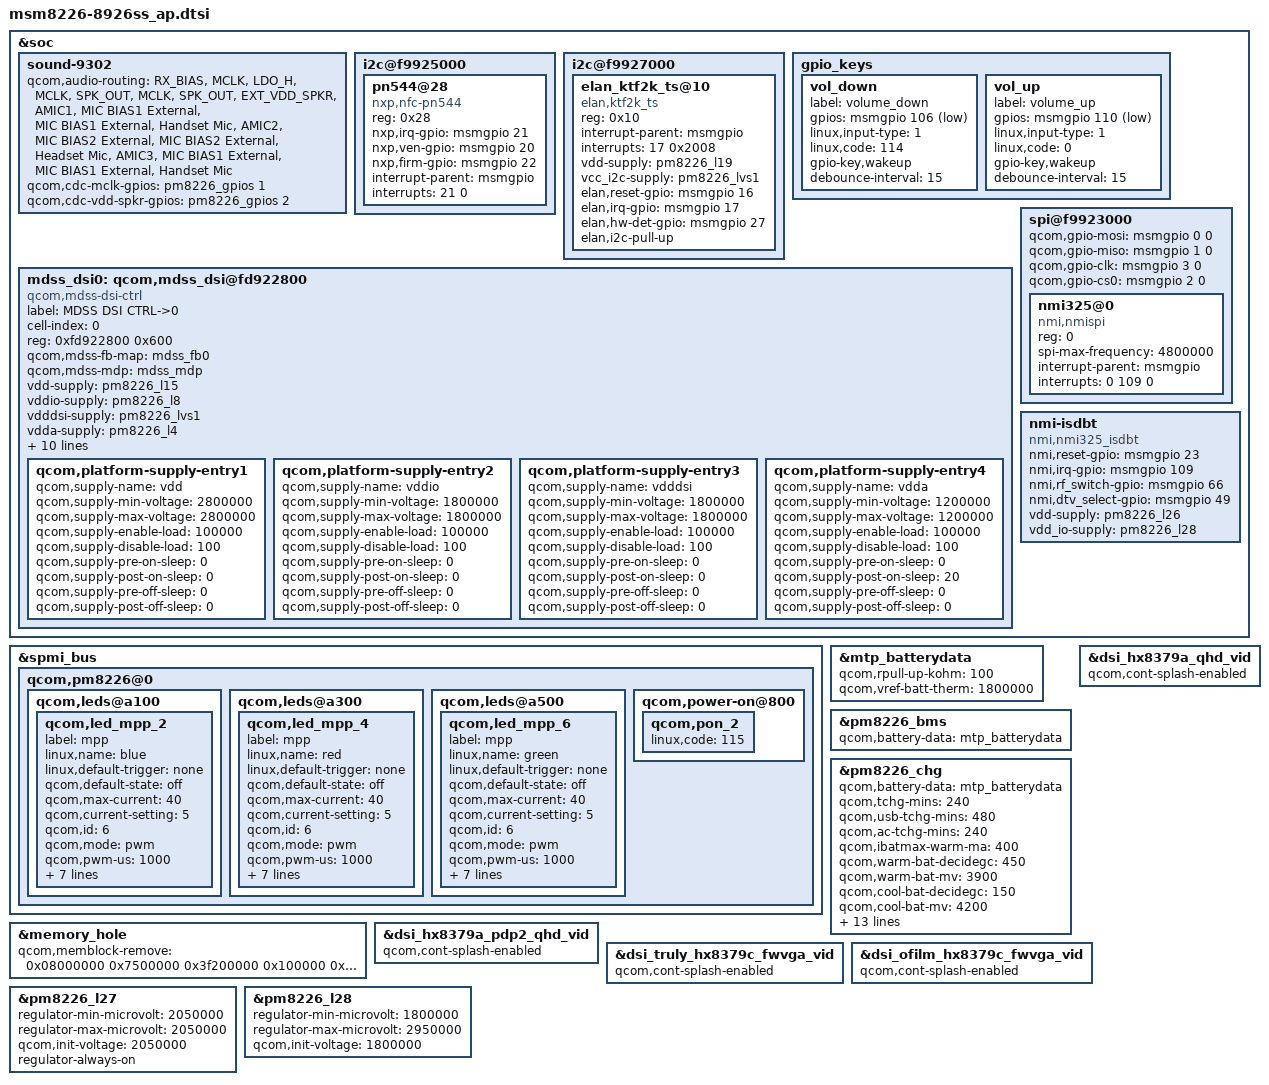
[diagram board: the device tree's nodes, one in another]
/include/ "msm8226-arima.dtsi"

/*[Arima5908][32703][StevenChen] LCM driver porting 2014/01/03 begin */
/include/ "dsi-panel-truly-hx8379a-qhd-video.dtsi"
/*[Arima5908][32703][StevenChen] LCM driver porting 2014/01/03 end */

/* --- [All][Main][Audio][DMS][LuboLu] Porting audio. 20140103 begin --- */
&soc {
	sound-9302 {
		qcom,audio-routing =
			"RX_BIAS", "MCLK",
			"LDO_H", "MCLK",
			"SPK_OUT", "MCLK",
			"SPK_OUT", "EXT_VDD_SPKR",
			"AMIC1", "MIC BIAS1 External",
			"MIC BIAS1 External", "Handset Mic",
			"AMIC2", "MIC BIAS2 External",
			"MIC BIAS2 External", "Headset Mic",
			"AMIC3", "MIC BIAS1 External",
			"MIC BIAS1 External", "Handset Mic";

		qcom,cdc-mclk-gpios = <&pm8226_gpios 1 0>;
		qcom,cdc-vdd-spkr-gpios = <&pm8226_gpios 2 0>;
	};
};
/* --- [All][Main][Audio][DMS][LuboLu] 20140103 end   --- */

/* --- [All][Main][NFC][DMS][LuboLu] Porting NFC(NXP PN547). 20140103 begin --- */
&soc {
		i2c@f9925000 { /* BLSP1 QUP3 */
		pn544@28 {
			compatible = "nxp,nfc-pn544";
			reg = <0x28>;
			nxp,irq-gpio = <&msmgpio 21 0x00>;
			nxp,ven-gpio = <&msmgpio 20 0x00>;
			nxp,firm-gpio = <&msmgpio 22 0x00>;
			interrupt-parent = <&msmgpio>;
			interrupts = <21 0>;
		};
	};
/* #//[All][Main][TP][32772]20140106,Eric, Porting elan-ektf3135 touch driver. */
               i2c@f9927000 { /* BLSP1 QUP5 */
		elan_ktf2k_ts@10{
			compatible = "elan,ktf2k_ts";
			reg = <0x10>;
			interrupt-parent = <&msmgpio>;
			interrupts = <17 0x2008>;
			vdd-supply = <&pm8226_l19>;
			vcc_i2c-supply = <&pm8226_lvs1>;
			elan,reset-gpio = <&msmgpio 16 0x00>;
			elan,irq-gpio = <&msmgpio 17 0x2008>;
			elan,hw-det-gpio = <&msmgpio 27 0x00>;			
			elan,i2c-pull-up;
		};
         };
/*   #//[All][Main][TP][32772]end */

/* [Arima5908][32780][JessicaTseng] [All][Main][Key][DMS]Porting volume_down key for PDP1 20140106 start */
	gpio_keys {
		vol_down {
			label = "volume_down";
			gpios = <&msmgpio 110 0x1>;
			linux,input-type = <1>;
			linux,code = <114>;
			gpio-key,wakeup;
			debounce-interval = <15>;
		};
	};
/* [Arima5908][32780][JessicaTseng] [All][Main][Key][DMS]Porting volume_down key for PDP1 20140106 end */
};
/* --- [All][Main][NFC][DMS][LuboLu] 20140103 end   --- */

/* [Arima5908][32708][JessicaTseng] [All][Main][LED][DMS]Porting R/G/B LED 20140103 start */
&spmi_bus {
	qcom,pm8226@0 {
		qcom,leds@a100 {
			status = "okay";
			qcom,led_mpp_2 {
				label = "mpp";
				linux,name = "blue";
				linux,default-trigger = "none";
				qcom,default-state = "off";
				qcom,max-current = <40>;
				qcom,current-setting = <5>;
				qcom,id = <6>;
				qcom,mode = "pwm";
				qcom,pwm-us = <1000>;
				qcom,source-sel = <14>;
				qcom,mode-ctrl = <0x60>;
				qcom,pwm-channel = <3>;
/* [Arima5908][33453][JessicaTseng] [All][Main][LED][DMS]Enable LED blinking function 20140127 start */
				qcom,start-idx = <40>;
/* [Arima5908][33453][JessicaTseng] [All][Main][LED][DMS]Enable LED blinking function 20140127 end */
				qcom,ramp-step-ms = <120>;
				qcom,duty-pcts = [00 00 50 99 99 99 50 00];
				qcom,use-blink;
			};
		};

		qcom,leds@a300 {
			status = "okay";
			qcom,led_mpp_4 {
				label = "mpp";
				linux,name = "green";
				linux,default-trigger = "none";
				qcom,default-state = "off";
				qcom,max-current = <40>;
				qcom,current-setting = <5>;
				qcom,id = <6>;
				qcom,mode = "pwm";
				qcom,pwm-us = <1000>;
				qcom,source-sel = <8>;
				qcom,mode-ctrl = <0x60>;
				qcom,pwm-channel = <0>;
/* [Arima5908][33453][JessicaTseng] [All][Main][LED][DMS]Enable LED blinking function 20140127 start */
				qcom,start-idx = <20>;
/* [Arima5908][33453][JessicaTseng] [All][Main][LED][DMS]Enable LED blinking function 20140127 end */
				qcom,ramp-step-ms = <120>;
				qcom,duty-pcts = [00 00 50 99 99 99 50 00];
				qcom,use-blink;
			};
		};

		qcom,leds@a500 {
			status = "okay";
			qcom,led_mpp_6 {
				label = "mpp";
				linux,name = "red";
				linux,default-trigger = "none";
				qcom,default-state = "off";
				qcom,max-current = <40>;
				qcom,current-setting = <5>;
				qcom,id = <6>;
				qcom,mode = "pwm";
				qcom,pwm-us = <1000>;
				qcom,mode-ctrl = <0x60>;
				qcom,source-sel = <10>;
				qcom,pwm-channel = <5>;
				qcom,start-idx = <1>;
				qcom,ramp-step-ms = <120>;
				qcom,duty-pcts = [00 00 50 99 99 99 50 00];
				qcom,use-blink;
			};
		};

/* [Arima5908][32719][JessicaTseng] [All][Main][KEY][DMS]Porting reset key 20140103 start */
		qcom,power-on@800 {
			qcom,pon_2 {
				linux,code = <0>;
			};
		};
/* [Arima5908][32719][JessicaTseng] [All][Main][KEY][DMS]Porting reset key 20140103 end */
	};
};
/* [Arima5908][32708][JessicaTseng] [All][Main][LED][DMS]Porting R/G/B LED 20140103 end */

/*[Arima5908][32742][bozhi_lin] modify battery capacity to 2300mA for BA950 20140108 begin*/
&mtp_batterydata{
	qcom,rpull-up-kohm = <100>;
	qcom,vref-batt-therm = <1800000>;
	/include/ "batterydata-8926ss_dp.dtsi"
};

&pm8226_bms {
	qcom,battery-data = <&mtp_batterydata>;
};

&pm8226_chg {
	qcom,battery-data = <&mtp_batterydata>;
};
/*[Arima5908][32742][bozhi_lin] 20140108 end  */

/*[Arima5908][32703][StevenChen] LCM driver porting 2014/01/03 begin */			
&mdss_dsi0 {
	qcom,dsi-pref-prim-pan = <&dsi_hx8379a_qhd_vid>;
};

&dsi_hx8379a_qhd_vid { 
	qcom,cont-splash-enabled;
};
/*[Arima5908][32703][StevenChen] LCM driver porting 2014/01/03 end */

// [All][Main][Ramdump][DMS][33956][akenhsu] Add a memory region (1Mb) for ramdump 20140218 BEGIN
&memory_hole {
	qcom,memblock-remove = <0x08000000 0x7500000
		0x3f200000 0x100000 // Add 1M from 0x3f200000 for restart_parameters
		0x0fa00000 0x500000>; /* Address and size of the hole */
};
// [All][Main][Ramdump][DMS][33956][akenhsu] 20140218 END


/*[Arima5908][32703][StevenChen] LCM driver porting 2014/01/03 begin */
/include/ "dsi-panel-truly-hx8379a-pdp2-qhd-video.dtsi"
/* [All][Main][LCM][DMS][39942][StevenChen] Update O-Film LCM driver 2014/06/20 begin */
/* [All][Main][LCM][DMS][38418][StevenChen] LCM auto detection for 2nd & 3rd source 2014/05/22 begin */
/include/ "dsi-panel-truly-hx8379c-fwvga-video.dtsi"
/include/ "dsi-panel-ofilm-hx8379c-fwvga-video.dtsi"
/* [All][Main][LCM][DMS][38418][StevenChen] LCM auto detection for 2nd & 3rd source 2014/05/22 end */
/* [All][Main][LCM][DMS][39942][StevenChen] Update O-Film LCM driver 2014/06/20 end */
/*[Arima5908][32703][StevenChen] LCM driver porting 2014/01/03 end */

/* [Arima5908][32719][JessicaTseng] [All][Main][KEY][DMS]Porting reset key 20140103 start */
&spmi_bus {
	qcom,pm8226@0 {
		qcom,power-on@800 {
			qcom,pon_2 {
				linux,code = <115>;
			};
		};
	};
};
/* [Arima5908][32719][JessicaTseng] [All][Main][KEY][DMS]Porting reset key 20140103 end */

/*[Arima5908][32703][StevenChen] LCM driver porting 2014/01/03 begin */
&mdss_dsi0 {
	qcom,dsi-pref-prim-pan = <&dsi_hx8379a_pdp2_qhd_vid>;	
};

/* [Arima5908][34570][StevenChen] Disable splash screen for S1 build release 2014/03/07 begin */
/* [Arima5908][34437][StevenChen] Rollback splash screen feature 2014/03/04 begin */
&dsi_hx8379a_pdp2_qhd_vid {
/* [All][Main][LCM][DMS05379061][35893][StevenChen] LCM continue splash on and change boot logo 2014/04/09 begin */
//<2014/02/20-34073-EricLin, Do not support splash screen in S1 solution.
	qcom,cont-splash-enabled;
//>2014/02/20-34073-EricLin
/* [All][Main][LCM][DMS05379061][35893][StevenChen] LCM continue splash on and change boot logo 2014/04/09 end */
};
/* [All][Main][LCM][DMS][38418][StevenChen] LCM auto detection for 2nd & 3rd source 2014/05/22 begin */
&dsi_truly_hx8379c_fwvga_vid {
	qcom,cont-splash-enabled;
};

/* [All][Main][LCM][DMS][39942][StevenChen] Update O-Film LCM driver 2014/06/20 begin */
&dsi_ofilm_hx8379c_fwvga_vid {
	qcom,cont-splash-enabled;
};
/* [All][Main][LCM][DMS][39942][StevenChen] Update O-Film LCM driver 2014/06/20 end */
/* [All][Main][LCM][DMS][38418][StevenChen] LCM auto detection for 2nd & 3rd source 2014/05/22 end */
/* [Arima5908][34437][StevenChen] Rollback splash screen feature 2014/03/04 end */
/* [Arima5908][34570][StevenChen] Disable splash screen for S1 build release 2014/03/07 end */
/*[Arima5908][32703][StevenChen] LCM driver porting 2014/01/03 end */

/* [All][Main][Display][DMS][35638][StevenChen] Fix no bootup screen issue 2014/04/02 begin */
/* [Arima5908][32747][JessicaTseng] [All][Main][Key][DMS]Using volume_up key enters download mode 20140104 start */
&soc {
	gpio_keys {
		vol_up {
			label = "volume_up";
			gpios = <&msmgpio 110 0x1>;
			linux,input-type = <1>;
			linux,code = <0>;
			gpio-key,wakeup;
			debounce-interval = <15>;
		};
		
		vol_down {
			label = "volume_down";
			gpios = <&msmgpio 106 0x1>;
			linux,input-type = <1>;
			linux,code = <114>;
			gpio-key,wakeup;
			debounce-interval = <15>;
		};
	};
	
	mdss_dsi0: qcom,mdss_dsi@fd922800 {
		compatible = "qcom,mdss-dsi-ctrl";
		label = "MDSS DSI CTRL->0";
		cell-index = <0>;
		reg = <0xfd922800 0x600>;
		qcom,mdss-fb-map = <&mdss_fb0>;
		qcom,mdss-mdp = <&mdss_mdp>;
		vdd-supply = <&pm8226_l15>;
		vddio-supply = <&pm8226_l8>;
		vdddsi-supply = <&pm8226_lvs1>;
		vdda-supply = <&pm8226_l4>;
		qcom,platform-reset-gpio = <&msmgpio 25 0>;
		qcom,platform-te-gpio = <&msmgpio 24 0>;
		qcom,platform-strength-ctrl = [ff 06];
		qcom,platform-bist-ctrl = [00 00 b1 ff 00 00];
		qcom,platform-regulator-settings = [07 09 03 00 20 00 01];
		qcom,platform-lane-config = [00 00 00 00 00 00 00 01 97
			00 00 00 00 05 00 00 01 97
			00 00 00 00 0a 00 00 01 97
			00 00 00 00 0f 00 00 01 97
			00 c0 00 00 00 00 00 01 bb];
		qcom,platform-supply-entry1 {
			qcom,supply-name = "vdd";
			qcom,supply-min-voltage = <2800000>;
			qcom,supply-max-voltage = <2800000>;
			qcom,supply-enable-load = <100000>;
			qcom,supply-disable-load = <100>;
			qcom,supply-pre-on-sleep = <0>;
			qcom,supply-post-on-sleep = <0>;
			qcom,supply-pre-off-sleep = <0>;
			qcom,supply-post-off-sleep = <0>;
		};
		qcom,platform-supply-entry2 {
			qcom,supply-name = "vddio";
			qcom,supply-min-voltage = <1800000>;
			qcom,supply-max-voltage = <1800000>;
			qcom,supply-enable-load = <100000>;
			qcom,supply-disable-load = <100>;
			qcom,supply-pre-on-sleep = <0>;
			qcom,supply-post-on-sleep = <0>;
			qcom,supply-pre-off-sleep = <0>;
			qcom,supply-post-off-sleep = <0>;
		};
		qcom,platform-supply-entry3 {
			qcom,supply-name = "vdddsi";
			qcom,supply-min-voltage = <1800000>;
			qcom,supply-max-voltage = <1800000>;
			qcom,supply-enable-load = <100000>;
			qcom,supply-disable-load = <100>;
			qcom,supply-pre-on-sleep = <0>;
			qcom,supply-post-on-sleep = <0>;
			qcom,supply-pre-off-sleep = <0>;
			qcom,supply-post-off-sleep = <0>;
		};
		qcom,platform-supply-entry4 {
			qcom,supply-name = "vdda";
			qcom,supply-min-voltage = <1200000>;
			qcom,supply-max-voltage = <1200000>;
			qcom,supply-enable-load = <100000>;
			qcom,supply-disable-load = <100>;
			qcom,supply-pre-on-sleep = <0>;
			qcom,supply-post-on-sleep = <20>;
			qcom,supply-pre-off-sleep = <0>;
			qcom,supply-post-off-sleep = <0>;
		};
	};
};
/* [Arima5908][32747][JessicaTseng] [All][Main][Key][DMS]Using volume_up key enters download mode 20140104 end */
/* [All][Main][Display][DMS][35638][StevenChen] Fix no bootup screen issue 2014/04/02 end */

&mtp_batterydata{
	qcom,rpull-up-kohm = <100>;
	qcom,vref-batt-therm = <1800000>;
	/include/ "batterydata-8926ss_dp.dtsi"
};

/*[Arima5908][32742][bozhi_lin] modify battery capacity to 2300mA for BA950 20140108 begin*/
&pm8226_bms {
	qcom,battery-data = <&mtp_batterydata>;
};

&pm8226_chg {
	qcom,battery-data = <&mtp_batterydata>;
/*[Arima5908][33960][JasonHsing] set charging timer to 4 hours 20140218 begin*/
	qcom,tchg-mins = <240>;
/*[Arima5908][33960][JasonHsing] 20140218 end  */
/*[Arima5911][35276][bozhi_lin] set safety timer USB to 8 hours and AD to 4 hours 20140325 begin*/
	qcom,usb-tchg-mins = <480>;
	qcom,ac-tchg-mins = <240>;
/*[Arima5911][35276][bozhi_lin] 20140325 end  */
/*[Arima5911][35561][bozhi_lin] set warm battery voltage to 3.9V caused by voltage will over 4V 20140401 begin*/
/*[Arima5911][33810][bozhi_lin] For charging safety: set warm battery state and cool battery state to meet requirement 20140321 begin*/
	qcom,ibatmax-warm-ma = <400>;
	qcom,warm-bat-decidegc = <450>;
	qcom,warm-bat-mv = <3900>;
	qcom,cool-bat-decidegc = <150>;
	qcom,cool-bat-mv = <4200>;
	qcom,ibatmax-cool-ma = <1500>;
	qcom,btc-disabled;
	qcom,hot-bat-decidegc = <550>;
	qcom,cold-bat-decidegc = <50>;
/*[Arima5911][33810][bozhi_lin] 20140321 end  */
/*[Arima5911][35561][bozhi_lin] 20140401 end  */
/*[Arima5911][33917][bozhi_lin] set a flag to enable charging timer to stop charging 20140321 begin*/
	qcom,charging-timer-enable;
/*[Arima5911][33917][bozhi_lin] 20140321 end  */
/*[Arima5908][36408][bozhi_lin] set vbatweak to 3.4V for charging fine tune 20140416 begin*/
	qcom,vbatweak-mv = <3400>;
/*[Arima5908][36408][bozhi_lin] 20140416 end  */
/*[Arima5911][34482][bozhi_lin] set VBAT_DET to 4V during call 20140328 begin*/
	qcom,call-bat-mv = <3900>;
/*[Arima5911][34482][bozhi_lin] 20140328 end  */
/*[Arima5911][35151][bozhi_lin] disable resume soc 20140321 begin*/
	qcom,resume-soc = <0>;
/*[Arima5911][35151][bozhi_lin] 20140321 end  */
/*[Arima5911][35152][bozhi_lin] set vbatdet and vbatmax to 4.15V when eoc 20140321 begin*/
	qcom,vbatdet-delta-mv = <50>;
/*[Arima5911][35152][bozhi_lin] 20140321 end  */
/*[Arima5908][36950][bozhi_lin] enable charging maintance 4.15V over 60hrs and 4.1V over 200hrs 20140425 begin*/
	qcom,first-maintain-mins = <3600>;//<3600>;
	qcom,second-maintain-mins = <12000>;//<12000>;
	qcom,first-maintain-mv = <4150>;
	qcom,second-maintain-mv = <4100>;
/*[Arima5908][36950][bozhi_lin] 20140425 end  */
};
/*[Arima5908][32742][bozhi_lin] 20140108 end  */


/*[Arima5908][33614][bozhi_lin] NMI326 dtv function porting 20140207 begin*/
&soc {
	spi@f9923000 {
		qcom,gpio-mosi = <&msmgpio 0 0>;
		qcom,gpio-miso = <&msmgpio 1 0>;
		qcom,gpio-clk  = <&msmgpio 3 0>;
		qcom,gpio-cs0  = <&msmgpio 2 0>;
		nmi325@0 {
			compatible = "nmi,nmispi"; 
			reg = <0>; 
			spi-max-frequency = <4800000>; 
			interrupt-parent = <&msmgpio>;
			interrupts = <0 109 0>;	
		};
	};

	nmi-isdbt{        
		compatible = "nmi,nmi325_isdbt";       
		nmi,reset-gpio = <&msmgpio 23 0x00>;
		nmi,irq-gpio = <&msmgpio 109 0x2008>;
		nmi,rf_switch-gpio = <&msmgpio 66 0x00>;
		nmi,dtv_select-gpio = <&msmgpio 49 0x00>;
		vdd-supply = <&pm8226_l26>;
		vdd_io-supply = <&pm8226_l28>;
	};
};
/*[Arima5908][33614][bozhi_lin] 20140207 end  */

/* [Arima5908][33547][JessicaTseng] [All][Main][LED][DMS]Modify LED configure for DP HW 20140204 start */
&spmi_bus {
	qcom,pm8226@0 {
		qcom,leds@a100 {
			status = "okay";
			qcom,led_mpp_2 {
				label = "mpp";
				linux,name = "blue";
				linux,default-trigger = "none";
				qcom,default-state = "off";
				qcom,max-current = <40>;
				qcom,current-setting = <5>;
				qcom,id = <6>;
				qcom,mode = "pwm";
				qcom,pwm-us = <1000>;
				qcom,source-sel = <14>;
				qcom,mode-ctrl = <0x60>;
				qcom,pwm-channel = <3>;
				qcom,start-idx = <40>;
				qcom,ramp-step-ms = <120>;
				qcom,duty-pcts = [00 00 50 99 99 99 50 00];
				qcom,use-blink;
			};
		};

		qcom,leds@a300 {
			status = "okay";
			qcom,led_mpp_4 {
				label = "mpp";
				linux,name = "red";
				linux,default-trigger = "none";
				qcom,default-state = "off";
				qcom,max-current = <40>;
				qcom,current-setting = <5>;
				qcom,id = <6>;
				qcom,mode = "pwm";
				qcom,pwm-us = <1000>;
				qcom,source-sel = <8>;
				qcom,mode-ctrl = <0x60>;
				qcom,pwm-channel = <0>;
				qcom,start-idx = <20>;
				qcom,ramp-step-ms = <120>;
				qcom,duty-pcts = [00 00 50 99 99 99 50 00];
				qcom,use-blink;
			};
		};

		qcom,leds@a500 {
			status = "okay";
			qcom,led_mpp_6 {
				label = "mpp";
				linux,name = "green";
				linux,default-trigger = "none";
				qcom,default-state = "off";
				qcom,max-current = <40>;
				qcom,current-setting = <5>;
				qcom,id = <6>;
				qcom,mode = "pwm";
				qcom,pwm-us = <1000>;
				qcom,mode-ctrl = <0x60>;
				qcom,source-sel = <10>;
				qcom,pwm-channel = <5>;
				qcom,start-idx = <1>;
				qcom,ramp-step-ms = <120>;
				qcom,duty-pcts = [00 00 50 99 99 99 50 00];
				qcom,use-blink;
			};
		};
	};
};
/* [Arima5908][33547][JessicaTseng] [All][Main][LED][DMS]Modify LED configure for DP HW 20140204 end */

/*[Arima5908][33614][bozhi_lin] NMI326 dtv function porting 20140207 begin*/
&pm8226_l27{
	regulator-min-microvolt = <2050000>;
	regulator-max-microvolt = <2050000>;
	qcom,init-voltage = <2050000>;
	regulator-always-on;
};

&pm8226_l28{
	regulator-min-microvolt = <1800000>;
	regulator-max-microvolt = <2950000>;
	qcom,init-voltage = <1800000>;
};
/*[Arima5908][33614][bozhi_lin] 20140207 end  */

/*[Arima5911][35440][bozhi_lin] apply Lucisus2_1458334_2330mAh battery data from QCT 20140328 begin*/
&mtp_batterydata{
	qcom,rpull-up-kohm = <100>;
	qcom,vref-batt-therm = <1800000>;
	/include/ "batterydata-8926ss_dp.dtsi"
};

&pm8226_bms {
	qcom,battery-data = <&mtp_batterydata>;
};

&pm8226_chg {
	qcom,battery-data = <&mtp_batterydata>;
};
/*[Arima5911][35440][bozhi_lin] 20140328 end  */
